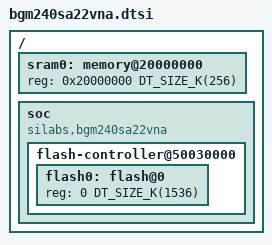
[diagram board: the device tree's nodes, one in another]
/*
 * Copyright (c) 2023 Fr. Sauter AG
 * Copyright (c) 2024 Jonny Gellhaar
 *
 * SPDX-License-Identifier: Apache-2.0
 */

#include <mem.h>
#include <silabs/bgm24.dtsi>

/ {
	sram0: memory@20000000 {
		reg = <0x20000000 DT_SIZE_K(256)>;
	};

	soc {
		compatible = "silabs,bgm240sa22vna",
					 "silabs,bgm24", "silabs,efr32",
					 "simple-bus";

		flash-controller@50030000 {
			flash0: flash@0 {
				reg = <0 DT_SIZE_K(1536)>;
			};
		};
	};
};
